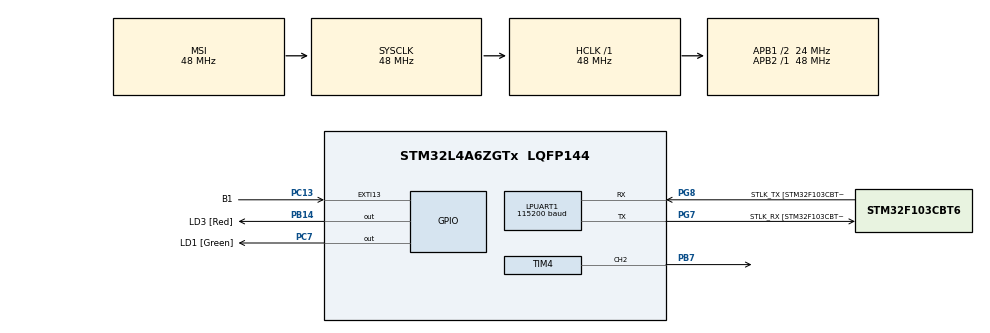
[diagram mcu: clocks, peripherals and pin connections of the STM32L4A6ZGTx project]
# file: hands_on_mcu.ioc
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LPUART1.AutoBaudRateEnableParam=UART_ADVFEATURE_AUTOBAUDRATE_DISABLE
LPUART1.BaudRate=115200
LPUART1.DMADisableonRxErrorParam=UART_ADVFEATURE_DMA_ENABLEONRXERROR
LPUART1.DataInvertParam=UART_ADVFEATURE_DATAINV_DISABLE
LPUART1.MSBFirstParam=UART_ADVFEATURE_MSBFIRST_DISABLE
LPUART1.Mode=UART_MODE_TX_RX
LPUART1.OneBitSampling=UART_ONE_BIT_SAMPLE_DISABLE
LPUART1.OverrunDisableParam=UART_ADVFEATURE_OVERRUN_ENABLE
LPUART1.Parity=UART_PARITY_NONE
LPUART1.RxPinLevelInvertParam=UART_ADVFEATURE_RXINV_DISABLE
LPUART1.StopBits=UART_STOPBITS_1
LPUART1.SwapParam=UART_ADVFEATURE_SWAP_DISABLE
LPUART1.TxPinLevelInvertParam=UART_ADVFEATURE_TXINV_DISABLE
LPUART1.WordLength=UART_WORDLENGTH_8B
Mcu.Family=STM32L4
Mcu.Name=STM32L4A6ZGTx
Mcu.Package=LQFP144
NVIC.EXTI15_10_IRQn=true\:0\:0\:false\:false\:true\:true\:true\:true
NVIC.PriorityGroup=NVIC_PRIORITYGROUP_4
PA13\ (JTMS/SWDIO).GPIO_Label=TMS
PA13\ (JTMS/SWDIO).Mode=Trace_Asynchronous_SW
PA13\ (JTMS/SWDIO).Signal=SYS_JTMS-SWDIO
PA14\ (JTCK/SWCLK).GPIO_Label=TCK
PA14\ (JTCK/SWCLK).Mode=Trace_Asynchronous_SW
PA14\ (JTCK/SWCLK).Signal=SYS_JTCK-SWCLK
PB14.GPIO_Label=LD3 [Red]
PB14.Signal=GPIO_Output
PB3\ (JTDO/TRACESWO).GPIO_Label=SWO
PB3\ (JTDO/TRACESWO).Mode=Trace_Asynchronous_SW
PB3\ (JTDO/TRACESWO).Signal=SYS_JTDO-SWO
PB7.Signal=S_TIM4_CH2
PC13.GPIO_Label=B1
PC13.Signal=GPXTI13
PC14-OSC32_IN\ (PC14).Mode=LSE-External-Oscillator
PC14-OSC32_IN\ (PC14).Signal=RCC_OSC32_IN
PC15-OSC32_OUT\ (PC15).Mode=LSE-External-Oscillator
PC15-OSC32_OUT\ (PC15).Signal=RCC_OSC32_OUT
PC7.GPIO_Label=LD1 [Green]
PC7.Signal=GPIO_Output
PG7.GPIO_Label=STLK_RX [STM32F103CBT6_PA3]
PG7.Mode=Asynchronous
PG7.Signal=LPUART1_TX
PG8.GPIO_Label=STLK_TX [STM32F103CBT6_PA2]
PG8.Mode=Asynchronous
PG8.Signal=LPUART1_RX
PH1-OSC_OUT\ (PH1).Signal=RCC_OSC_OUT
ProjectManager.HeapSize=0x200
ProjectManager.StackSize=0x400
ProjectManager.TargetToolchain=STM32CubeIDE
RCC.ADCFreq_Value=576000000
RCC.AHBFreq_Value=48000000
RCC.APB1CLKDivider=RCC_HCLK_DIV2
RCC.APB1Freq_Value=24000000
RCC.APB1TimFreq_Value=48000000
RCC.APB2Freq_Value=48000000
RCC.APB2TimFreq_Value=48000000
RCC.CortexFreq_Value=48000000
RCC.FLatency=FLASH_LATENCY_2
RCC.HCLKFreq_Value=48000000
RCC.HSE_VALUE=8000000
RCC.HSI48_VALUE=48000000
RCC.HSI_VALUE=16000000
RCC.MSIClockRange=RCC_MSIRANGE_11
RCC.MSI_VALUE=48000000
RCC.PLLN=71
RCC.PLLR=RCC_PLLR_DIV6
RCC.PLLSAI1N=24
RCC.SYSCLKFreq_VALUE=48000000
RCC.USBFreq_Value=576000000
RCC.VCOOutputFreq_Value=3408000000
SH.S_TIM4_CH2.0=TIM4_CH2,Output Compare2 CH2
TIM4.Channel-Output\ Compare2\ CH2=TIM_CHANNEL_2
TIM4.OCMode_2=TIM_OCMODE_TOGGLE
TIM4.Period=499
TIM4.Prescaler=31199
TIM4.Pulse-Output\ Compare2\ CH2=0
VP_TIM4_VS_ClockSourceINT.Mode=Internal
board=NUCLEO-L4A6ZG

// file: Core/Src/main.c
/* USER CODE BEGIN Header */
/**
  ******************************************************************************
  * @file           : main.c
  * @brief          : Main program body
  ******************************************************************************
  * @attention
  *
  * <h2><center>&copy; Copyright (c) 2021 STMicroelectronics.
  * All rights reserved.</center></h2>
  *
  * This software component is licensed by ST under BSD 3-Clause license,
  * the "License"; You may not use this file except in compliance with the
  * License. You may obtain a copy of the License at:
  *                        opensource.org/licenses/BSD-3-Clause
  *
  ******************************************************************************
  */
/* USER CODE END Header */
#include "main.h"
#include "usart.h"
#include "tim.h"
#include "gpio.h"

/* USER CODE BEGIN Includes */
#include <stdio.h>
#include "retarget.h"
/* USER CODE END Includes */

/* USER CODE BEGIN PV */
	int light = 0;
//	int count = 0;
	void HAL_GPIO_EXTI_Callback(uint16_t GPIO_Pin) {
		if (GPIO_Pin == B1_Pin) {
			if(light == 1) {
				light = 0;
				HAL_TIM_OC_Start(&htim4, TIM_CHANNEL_2);
//				count += 1;
//				printf("%d", count);
//				printf("Light off\r\n");
			} else {
				light = 1;
				HAL_TIM_OC_Stop(&htim4, TIM_CHANNEL_2);
//				count += 1;
//				printf("%d", count);
//				printf("Light on\r\n");
			}
		}
	}
/* USER CODE END PV */

void SystemClock_Config(void);

int main(void)
{

  /* MCU Configuration--------------------------------------------------------*/

  /* Reset of all peripherals, Initializes the Flash interface and the Systick. */
  HAL_Init();

  /* Configure the system clock */
  SystemClock_Config();

  /* Initialize all configured peripherals */
  MX_GPIO_Init();
  MX_LPUART1_UART_Init();
  MX_TIM4_Init();
  /* USER CODE BEGIN 2 */
  RetargetInit(&hlpuart1);
  printf("Hello world!\r\n");

  /* USER CODE END 2 */

  /* Infinite loop */
  /* USER CODE BEGIN WHILE */
  HAL_Delay(500);
  while (1)
  {
//	  __WFI();
//	  if(light == 1) {
//		  HAL_GPIO_WritePin(LD2_GPIO_Port, LD2_Pin, GPIO_PIN_SET);
//		  HAL_Delay(500);
//		  HAL_GPIO_WritePin(LD2_GPIO_Port, LD2_Pin, GPIO_PIN_RESET);
//		  HAL_Delay(500);
//	  }
//	  if (pressed == 0) {
//		  if (HAL_GPIO_ReadPin(B1_GPIO_Port, B1_Pin) == 1) {
//			  pressed = 1;
//		  }
//	  }
//	  else {
//		  HAL_GPIO_WritePin(LD2_GPIO_Port, LD2_Pin, GPIO_PIN_SET);
//		  HAL_Delay(500);
//		  HAL_GPIO_WritePin(LD2_GPIO_Port, LD2_Pin, GPIO_PIN_RESET);
//		  HAL_Delay(500);
//		  if (HAL_GPIO_ReadPin(B1_GPIO_Port, B1_Pin) == 1) {
//			  pressed = 0;
//			  HAL_Delay(500);
//		  }
//	  }
    /* USER CODE END WHILE */

  }
}

void SystemClock_Config(void)
{
  RCC_OscInitTypeDef RCC_OscInitStruct = {0};
  RCC_ClkInitTypeDef RCC_ClkInitStruct = {0};

  /** Configure the main internal regulator output voltage
  */
  if (HAL_PWREx_ControlVoltageScaling(PWR_REGULATOR_VOLTAGE_SCALE1) != HAL_OK)
  {
    Error_Handler();
  }

  /** Initializes the RCC Oscillators according to the specified parameters
  * in the RCC_OscInitTypeDef structure.
  */
  RCC_OscInitStruct.OscillatorType = RCC_OSCILLATORTYPE_MSI;
  RCC_OscInitStruct.MSIState = RCC_MSI_ON;
  RCC_OscInitStruct.MSICalibrationValue = 0;
  RCC_OscInitStruct.MSIClockRange = RCC_MSIRANGE_11;
  RCC_OscInitStruct.PLL.PLLState = RCC_PLL_NONE;
  if (HAL_RCC_OscConfig(&RCC_OscInitStruct) != HAL_OK)
  {
    Error_Handler();
  }

  /** Initializes the CPU, AHB and APB buses clocks
  */
  RCC_ClkInitStruct.ClockType = RCC_CLOCKTYPE_HCLK|RCC_CLOCKTYPE_SYSCLK
                              |RCC_CLOCKTYPE_PCLK1|RCC_CLOCKTYPE_PCLK2;
  RCC_ClkInitStruct.SYSCLKSource = RCC_SYSCLKSOURCE_MSI;
  RCC_ClkInitStruct.AHBCLKDivider = RCC_SYSCLK_DIV1;
  RCC_ClkInitStruct.APB1CLKDivider = RCC_HCLK_DIV2;
  RCC_ClkInitStruct.APB2CLKDivider = RCC_HCLK_DIV1;

  if (HAL_RCC_ClockConfig(&RCC_ClkInitStruct, FLASH_LATENCY_2) != HAL_OK)
  {
    Error_Handler();
  }
}

void Error_Handler(void)
{
  __disable_irq();
  while (1)
  {
  }
}
